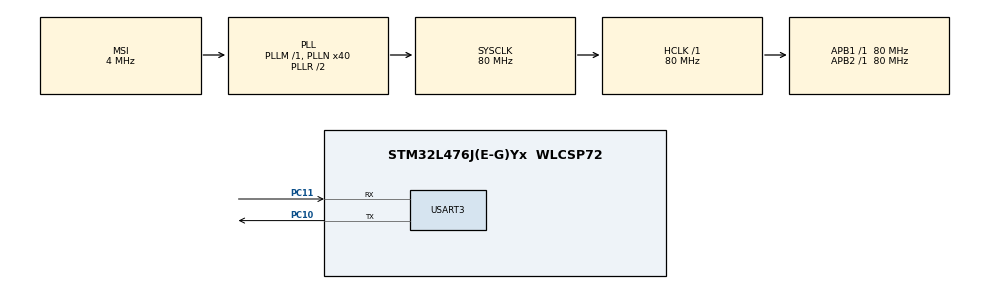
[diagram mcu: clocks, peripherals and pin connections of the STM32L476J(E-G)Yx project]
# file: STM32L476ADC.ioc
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ADC1.Channel-0\#ChannelRegularConversion=ADC_CHANNEL_VBAT
ADC1.ClockPrescaler=ADC_CLOCK_ASYNC_DIV8
ADC1.ContinuousConvMode=DISABLE
ADC1.DMAContinuousRequests=DISABLE
ADC1.DataAlign=ADC_DATAALIGN_RIGHT
ADC1.DiscontinuousConvMode=DISABLE
ADC1.EOCSelection=ADC_EOC_SINGLE_CONV
ADC1.EnableAnalogWatchDog1=false
ADC1.EnableAnalogWatchDog2=false
ADC1.EnableAnalogWatchDog3=false
ADC1.EnableInjectedConversion=DISABLE
ADC1.EnableRegularConversion=ENABLE
ADC1.ExternalTrigConv=ADC_SOFTWARE_START
ADC1.ExternalTrigConvEdge=ADC_EXTERNALTRIGCONVEDGE_NONE
ADC1.LowPowerAutoWait=DISABLE
ADC1.NbrOfConversion=1
ADC1.NbrOfConversionFlag=1
ADC1.OffsetNumber-0\#ChannelRegularConversion=ADC_OFFSET_NONE
ADC1.Overrun=ADC_OVR_DATA_PRESERVED
ADC1.OversamplingMode=DISABLE
ADC1.Rank-0\#ChannelRegularConversion=1
ADC1.Resolution=ADC_RESOLUTION_12B
ADC1.SamplingTime-0\#ChannelRegularConversion=ADC_SAMPLETIME_6CYCLES_5
ADC1.ScanConvMode=ADC_SCAN_DISABLE
ADC1.master=1
Mcu.Family=STM32L4
Mcu.Name=STM32L476J(E-G)Yx
Mcu.Package=WLCSP72
NVIC.PriorityGroup=NVIC_PRIORITYGROUP_4
NVIC.USART3_IRQn=true\:0\:0\:false\:false\:true\:true
PA13\ (JTMS-SWDIO).Mode=Serial_Wire
PA13\ (JTMS-SWDIO).Signal=SYS_JTMS-SWDIO
PA14\ (JTCK-SWCLK).Mode=Serial_Wire
PA14\ (JTCK-SWCLK).Signal=SYS_JTCK-SWCLK
PC10.Mode=Asynchronous
PC10.Signal=USART3_TX
PC11.Mode=Asynchronous
PC11.Signal=USART3_RX
PH0-OSC_IN\ (PH0).Mode=HSE-External-Oscillator
PH0-OSC_IN\ (PH0).Signal=RCC_OSC_IN
PH1-OSC_OUT\ (PH1).Mode=HSE-External-Oscillator
PH1-OSC_OUT\ (PH1).Signal=RCC_OSC_OUT
ProjectManager.HeapSize=0x200
ProjectManager.StackSize=0x400
ProjectManager.TargetToolchain=MDK-ARM V5
RCC.ADCCLockSelection=RCC_ADCCLKSOURCE_PLLSAI2
RCC.ADCFreq_Value=80000000
RCC.AHBFreq_Value=80000000
RCC.APB1Freq_Value=80000000
RCC.APB1TimFreq_Value=80000000
RCC.APB2Freq_Value=80000000
RCC.APB2TimFreq_Value=80000000
RCC.CortexFreq_Value=80000000
RCC.HCLKFreq_Value=80000000
RCC.HSE_VALUE=8000000
RCC.HSI_VALUE=16000000
RCC.LSE_VALUE=32768
RCC.MSI_VALUE=4000000
RCC.PLLN=40
RCC.PLLSAI1N=16
RCC.PLLSAI2N=40
RCC.SYSCLKFreq_VALUE=80000000
RCC.SYSCLKSource=RCC_SYSCLKSOURCE_PLLCLK
RCC.USBFreq_Value=32000000
RCC.VCOOutputFreq_Value=160000000
USART3.VirtualMode-Asynchronous=VM_ASYNC
VP_ADC1_Vbat_Input.Mode=IN-Vbat
VP_ADC1_Vref_Input.Mode=IN-Vrefint
board=custom

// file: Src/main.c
/**
  ******************************************************************************
  * @file           : main.c
  * @brief          : Main program body
  ******************************************************************************
  ** This notice applies to any and all portions of this file
  * that are not between comment pairs USER CODE BEGIN and
  * USER CODE END. Other portions of this file, whether
  * inserted by the user or by software development tools
  * are owned by their respective copyright owners.
  *
  * COPYRIGHT(c) 2018 STMicroelectronics
  *
  * Redistribution and use in source and binary forms, with or without modification,
  * are permitted provided that the following conditions are met:
  *   1. Redistributions of source code must retain the above copyright notice,
  *      this list of conditions and the following disclaimer.
  *   2. Redistributions in binary form must reproduce the above copyright notice,
  *      this list of conditions and the following disclaimer in the documentation
  *      and/or other materials provided with the distribution.
  *   3. Neither the name of STMicroelectronics nor the names of its contributors
  *      may be used to endorse or promote products derived from this software
  *      without specific prior written permission.
  *
  * THIS SOFTWARE IS PROVIDED BY THE COPYRIGHT HOLDERS AND CONTRIBUTORS "AS IS"
  * AND ANY EXPRESS OR IMPLIED WARRANTIES, INCLUDING, BUT NOT LIMITED TO, THE
  * IMPLIED WARRANTIES OF MERCHANTABILITY AND FITNESS FOR A PARTICULAR PURPOSE ARE
  * DISCLAIMED. IN NO EVENT SHALL THE COPYRIGHT HOLDER OR CONTRIBUTORS BE LIABLE
  * FOR ANY DIRECT, INDIRECT, INCIDENTAL, SPECIAL, EXEMPLARY, OR CONSEQUENTIAL
  * DAMAGES (INCLUDING, BUT NOT LIMITED TO, PROCUREMENT OF SUBSTITUTE GOODS OR
  * SERVICES; LOSS OF USE, DATA, OR PROFITS; OR BUSINESS INTERRUPTION) HOWEVER
  * CAUSED AND ON ANY THEORY OF LIABILITY, WHETHER IN CONTRACT, STRICT LIABILITY,
  * OR TORT (INCLUDING NEGLIGENCE OR OTHERWISE) ARISING IN ANY WAY OUT OF THE USE
  * OF THIS SOFTWARE, EVEN IF ADVISED OF THE POSSIBILITY OF SUCH DAMAGE.
  *
  ******************************************************************************
  */
#include "main.h"
#include "stm32l4xx_hal.h"
#include "adc.h"
#include "usart.h"
#include "gpio.h"

/* USER CODE BEGIN PV */
/* Private variables ---------------------------------------------------------*/
uint16_t AD_Value = 0;
float Vbat = 0;
/* USER CODE END PV */

void SystemClock_Config(void);

/* USER CODE BEGIN PFP */
/* Private function prototypes -----------------------------------------------*/

/* USER CODE END PFP */

int main(void)
{

  /* MCU Configuration----------------------------------------------------------*/

  /* Reset of all peripherals, Initializes the Flash interface and the Systick. */
  HAL_Init();

  /* Configure the system clock */
  SystemClock_Config();

  /* Initialize all configured peripherals */
  MX_GPIO_Init();
  MX_ADC1_Init();
  MX_USART3_UART_Init();

  /* Infinite loop */
  /* USER CODE BEGIN WHILE */
  while (1)
  {
//		printf("\n\r welcome to www.waveshere.com !!!\r\n");
		HAL_Delay(1000);

  /* USER CODE END WHILE */

  /* USER CODE BEGIN 3 */
		HAL_ADC_Start(&hadc1);
		HAL_ADC_PollForConversion(&hadc1, 50);
		 if(HAL_IS_BIT_SET(HAL_ADC_GetState(&hadc1), HAL_ADC_STATE_REG_EOC))
			 {
				 AD_Value = HAL_ADC_GetValue(&hadc1);
				 printf("Vbat ADC Vaul: %d\r\n",AD_Value);
				 			 Vbat =(float)((AD_Value)*(3.3/4095))*3+0.5;
			 printf("Vbat: %.6f V\r\n",Vbat);
			 }
		 HAL_Delay(1000);
		 }
  /* USER CODE END 3 */

}

void SystemClock_Config(void)
{

  RCC_OscInitTypeDef RCC_OscInitStruct;
  RCC_ClkInitTypeDef RCC_ClkInitStruct;
  RCC_PeriphCLKInitTypeDef PeriphClkInit;

    /**Initializes the CPU, AHB and APB busses clocks
    */
  RCC_OscInitStruct.OscillatorType = RCC_OSCILLATORTYPE_MSI;
  RCC_OscInitStruct.MSIState = RCC_MSI_ON;
  RCC_OscInitStruct.MSICalibrationValue = 0;
  RCC_OscInitStruct.MSIClockRange = RCC_MSIRANGE_6;
  RCC_OscInitStruct.PLL.PLLState = RCC_PLL_ON;
  RCC_OscInitStruct.PLL.PLLSource = RCC_PLLSOURCE_MSI;
  RCC_OscInitStruct.PLL.PLLM = 1;
  RCC_OscInitStruct.PLL.PLLN = 40;
  RCC_OscInitStruct.PLL.PLLP = RCC_PLLP_DIV7;
  RCC_OscInitStruct.PLL.PLLQ = RCC_PLLQ_DIV2;
  RCC_OscInitStruct.PLL.PLLR = RCC_PLLR_DIV2;
  if (HAL_RCC_OscConfig(&RCC_OscInitStruct) != HAL_OK)
  {
    _Error_Handler(__FILE__, __LINE__);
  }

    /**Initializes the CPU, AHB and APB busses clocks
    */
  RCC_ClkInitStruct.ClockType = RCC_CLOCKTYPE_HCLK|RCC_CLOCKTYPE_SYSCLK
                              |RCC_CLOCKTYPE_PCLK1|RCC_CLOCKTYPE_PCLK2;
  RCC_ClkInitStruct.SYSCLKSource = RCC_SYSCLKSOURCE_PLLCLK;
  RCC_ClkInitStruct.AHBCLKDivider = RCC_SYSCLK_DIV1;
  RCC_ClkInitStruct.APB1CLKDivider = RCC_HCLK_DIV1;
  RCC_ClkInitStruct.APB2CLKDivider = RCC_HCLK_DIV1;

  if (HAL_RCC_ClockConfig(&RCC_ClkInitStruct, FLASH_LATENCY_4) != HAL_OK)
  {
    _Error_Handler(__FILE__, __LINE__);
  }

  PeriphClkInit.PeriphClockSelection = RCC_PERIPHCLK_USART3|RCC_PERIPHCLK_ADC;
  PeriphClkInit.Usart3ClockSelection = RCC_USART3CLKSOURCE_PCLK1;
  PeriphClkInit.AdcClockSelection = RCC_ADCCLKSOURCE_PLLSAI2;
  PeriphClkInit.PLLSAI2.PLLSAI2Source = RCC_PLLSOURCE_MSI;
  PeriphClkInit.PLLSAI2.PLLSAI2M = 1;
  PeriphClkInit.PLLSAI2.PLLSAI2N = 40;
  PeriphClkInit.PLLSAI2.PLLSAI2P = RCC_PLLP_DIV7;
  PeriphClkInit.PLLSAI2.PLLSAI2R = RCC_PLLR_DIV2;
  PeriphClkInit.PLLSAI2.PLLSAI2ClockOut = RCC_PLLSAI2_ADC2CLK;
  if (HAL_RCCEx_PeriphCLKConfig(&PeriphClkInit) != HAL_OK)
  {
    _Error_Handler(__FILE__, __LINE__);
  }

    /**Configure the main internal regulator output voltage
    */
  if (HAL_PWREx_ControlVoltageScaling(PWR_REGULATOR_VOLTAGE_SCALE1) != HAL_OK)
  {
    _Error_Handler(__FILE__, __LINE__);
  }

    /**Configure the Systick interrupt time
    */
  HAL_SYSTICK_Config(HAL_RCC_GetHCLKFreq()/1000);

    /**Configure the Systick
    */
  HAL_SYSTICK_CLKSourceConfig(SYSTICK_CLKSOURCE_HCLK);

  /* SysTick_IRQn interrupt configuration */
  HAL_NVIC_SetPriority(SysTick_IRQn, 0, 0);
}

void _Error_Handler(char *file, int line)
{
  while(1)
  {
  }
}

/************************ (C) COPYRIGHT STMicroelectronics *****END OF FILE****/
